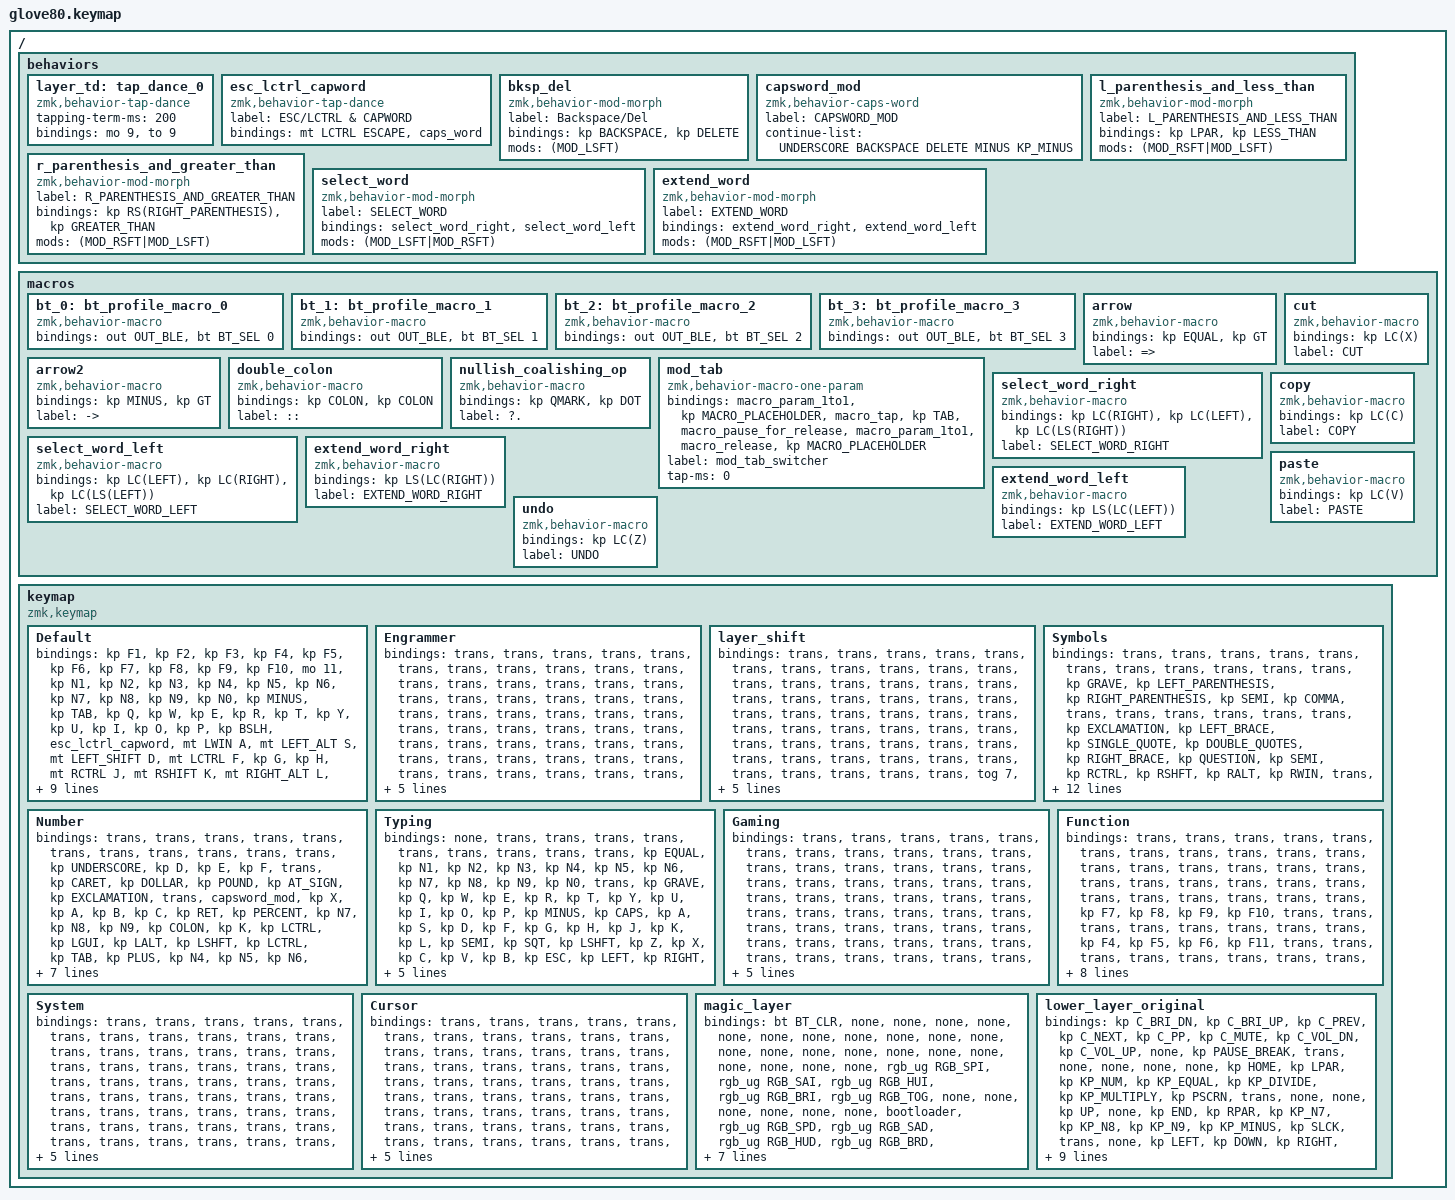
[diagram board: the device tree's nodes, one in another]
/*
 * Copyright (c) 2020 The ZMK Contributors
 *
 * SPDX-License-Identifier: MIT
 */

#include <behaviors.dtsi>
#include <dt-bindings/zmk/bt.h>
#include <dt-bindings/zmk/keys.h>
#include <dt-bindings/zmk/outputs.h>
#include <dt-bindings/zmk/rgb.h>

// layers

#define DEFAULT 0
#define LOWER 1
#define MAGIC 2

/ {
    behaviors {
        // For the "layer" key, it'd nice to be able to use it as either a shift or a toggle.
        // Configure it as a tap dance, so the first tap (or hold) is a &mo and the second tap is a &to

        layer_td: tap_dance_0 {
            compatible = "zmk,behavior-tap-dance";
            #binding-cells = <0>;
            tapping-term-ms = <200>;
            bindings = <&mo 9>, <&to 9>;
        };

        esc_lctrl_capword: esc_lctrl_capword {
            compatible = "zmk,behavior-tap-dance";
            label = "ESC/LCTRL & CAPWORD";
            #binding-cells = <0>;
            bindings = <&mt LCTRL ESCAPE>, <&caps_word>;
        };

        bksp_del: bksp_del {
            compatible = "zmk,behavior-mod-morph";
            label = "Backspace/Del";
            bindings = <&kp BACKSPACE>, <&kp DELETE>;

            #binding-cells = <0>;
            mods = <(MOD_LSFT)>;
        };

        capsword_mod: capsword_mod {
            compatible = "zmk,behavior-caps-word";
            label = "CAPSWORD_MOD";
            #binding-cells = <0>;
            continue-list = <UNDERSCORE BACKSPACE DELETE MINUS KP_MINUS>;
        };

        l_parenthesis_and_less_than: l_parenthesis_and_less_than {
            compatible = "zmk,behavior-mod-morph";
            label = "L_PARENTHESIS_AND_LESS_THAN";
            bindings = <&kp LPAR>, <&kp LESS_THAN>;

            #binding-cells = <0>;
            mods = <(MOD_RSFT|MOD_LSFT)>;
        };

        r_parenthesis_and_greater_than: r_parenthesis_and_greater_than {
            compatible = "zmk,behavior-mod-morph";
            label = "R_PARENTHESIS_AND_GREATER_THAN";
            bindings = <&kp RS(RIGHT_PARENTHESIS)>, <&kp GREATER_THAN>;

            #binding-cells = <0>;
            mods = <(MOD_RSFT|MOD_LSFT)>;
        };

        select_word: select_word {
            compatible = "zmk,behavior-mod-morph";
            label = "SELECT_WORD";
            bindings = <&select_word_right>, <&select_word_left>;

            #binding-cells = <0>;
            mods = <(MOD_LSFT|MOD_RSFT)>;
        };

        extend_word: extend_word {
            compatible = "zmk,behavior-mod-morph";
            label = "EXTEND_WORD";
            bindings = <&extend_word_right>, <&extend_word_left>;

            #binding-cells = <0>;
            mods = <(MOD_RSFT|MOD_LSFT)>;
        };
    };

    macros {
        bt_0: bt_profile_macro_0 {
            compatible = "zmk,behavior-macro";
            #binding-cells = <0>;
            bindings = <&out OUT_BLE &bt BT_SEL 0>;
        };

        bt_1: bt_profile_macro_1 {
            compatible = "zmk,behavior-macro";
            #binding-cells = <0>;
            bindings = <&out OUT_BLE &bt BT_SEL 1>;
        };

        bt_2: bt_profile_macro_2 {
            compatible = "zmk,behavior-macro";
            #binding-cells = <0>;
            bindings = <&out OUT_BLE &bt BT_SEL 2>;
        };

        bt_3: bt_profile_macro_3 {
            compatible = "zmk,behavior-macro";
            #binding-cells = <0>;
            bindings = <&out OUT_BLE &bt BT_SEL 3>;
        };

        arrow: arrow {
            compatible = "zmk,behavior-macro";
            #binding-cells = <0>;
            bindings = <&kp EQUAL &kp GT>;
            label = "=>";
        };

        arrow2: arrow2 {
            compatible = "zmk,behavior-macro";
            #binding-cells = <0>;
            bindings = <&kp MINUS &kp GT>;
            label = "->";
        };

        double_colon: double_colon {
            compatible = "zmk,behavior-macro";
            #binding-cells = <0>;
            bindings = <&kp COLON &kp COLON>;
            label = "::";
        };

        nullish_coalishing_op: nullish_coalishing_op {
            compatible = "zmk,behavior-macro";
            #binding-cells = <0>;
            bindings = <&kp QMARK &kp DOT>;
            label = "?.";
        };

        mod_tab: mod_tab {
            compatible = "zmk,behavior-macro-one-param";
            #binding-cells = <1>;
            bindings =
                <&macro_param_1to1 &kp MACRO_PLACEHOLDER>,
                <&macro_tap>,
                <&kp TAB>,
                <&macro_pause_for_release>,
                <&macro_param_1to1>,
                <&macro_release>,
                <&kp MACRO_PLACEHOLDER>;

            label = "mod_tab_switcher";
            tap-ms = <0>;
        };

        select_word_right: select_word_right {
            compatible = "zmk,behavior-macro";
            #binding-cells = <0>;
            bindings = <&kp LC(RIGHT) &kp LC(LEFT) &kp LC(LS(RIGHT))>;
            label = "SELECT_WORD_RIGHT";
        };

        select_word_left: select_word_left {
            compatible = "zmk,behavior-macro";
            #binding-cells = <0>;
            bindings = <&kp LC(LEFT) &kp LC(RIGHT) &kp LC(LS(LEFT))>;
            label = "SELECT_WORD_LEFT";
        };

        extend_word_right: extend_word_right {
            compatible = "zmk,behavior-macro";
            #binding-cells = <0>;
            bindings = <&kp LS(LC(RIGHT))>;
            label = "EXTEND_WORD_RIGHT";
        };

        extend_word_left: extend_word_left {
            compatible = "zmk,behavior-macro";
            #binding-cells = <0>;
            bindings = <&kp LS(LC(LEFT))>;
            label = "EXTEND_WORD_LEFT";
        };

        cut: cut {
            compatible = "zmk,behavior-macro";
            #binding-cells = <0>;
            bindings = <&kp LC(X)>;
            label = "CUT";
        };

        copy: copy {
            compatible = "zmk,behavior-macro";
            #binding-cells = <0>;
            bindings = <&kp LC(C)>;
            label = "COPY";
        };

        paste: paste {
            compatible = "zmk,behavior-macro";
            #binding-cells = <0>;
            bindings = <&kp LC(V)>;
            label = "PASTE";
        };

        undo: undo {
            compatible = "zmk,behavior-macro";
            #binding-cells = <0>;
            bindings = <&kp LC(Z)>;
            label = "UNDO";
        };
    };

    keymap {
        compatible = "zmk,keymap";

        Default {
            // ---------------------------------------------------------------------------------------------------------------------------------
            // |  F1   |  F2 |  F3 |  F4  |  F5  |                                                               |  F6   |  F7   |  F8  |   F9  |  F10 |
            // |  =    |  1  |  2  |  3   |  4   |  5   |                                                 |  6   |   7   |   8   |  9   |   0   |   -  |
            // |  TAB  |  Q  |  W  |  E   |  R   |  T   |                                                 |  Y   |   U   |   I   |  O   |   P   |   \  |
            // |  ESC  |  A  |  S  |  D   |  F   |  G   |                                                 |  H   |   J   |   K   |  L   |   ;   |   '  |
            // |   `   |  Z  |  X  |  C   |  V   |  B   | LSHFT | LCTRL | LOWER | | LGUI  | RCTRL | RSHFT |  N   |   M   |   ,   |  .   |   /   | PGUP |
            // | MAGIC | HOME| END | LEFT | RIGHT|      | BSPC  | DEL   | LALT  | | RALT  | RET   | SPACE |      |  UP   | DOWN  |  [   |   ]   | PGDN |

            bindings = <
&kp F1                       &kp F2      &kp F3          &kp F4            &kp F5                                                                                          &kp F6       &kp F7        &kp F8           &kp F9              &kp F10
&mo 11                       &kp N1      &kp N2          &kp N3            &kp N4       &kp N5                                                                     &kp N6  &kp N7       &kp N8        &kp N9           &kp N0              &kp MINUS
&kp TAB                      &kp Q       &kp W           &kp E             &kp R        &kp T                                                                      &kp Y   &kp U        &kp I         &kp O            &kp P               &kp BSLH
&esc_lctrl_capword           &mt LWIN A  &mt LEFT_ALT S  &mt LEFT_SHIFT D  &mt LCTRL F  &kp G                                                                      &kp H   &mt RCTRL J  &mt RSHIFT K  &mt RIGHT_ALT L  &mt RWIN SEMICOLON  &kp SQT
&mt LSHIFT LEFT_PARENTHESIS  &kp Z       &kp X           &kp C             &kp V        &kp B   &kp LSHFT  &kp LCTRL  &layer_td    &kp LGUI  &kp RCTRL  &kp RSHFT  &kp N   &kp M        &kp COMMA     &kp DOT          &kp SLASH           &mt RSHIFT RPAR
&mo 10                       &kp TILDE   &kp END         &kp LEFT          &kp RIGHT            &kp SPACE  &bksp_del  &sl 2        &sl 2     &kp TAB    &kp ENTER          &kp UP       &kp DOWN      &kp LBKT         &kp UNDERSCORE      &mo 10
            >;
        };

        Engrammer {
            bindings = <
&trans  &trans  &trans  &trans  &trans                                                                    &trans  &trans  &trans  &trans  &trans
&trans  &trans  &trans  &trans  &trans  &trans                                                    &trans  &trans  &trans  &trans  &trans  &trans
&trans  &trans  &trans  &trans  &trans  &trans                                                    &trans  &trans  &trans  &trans  &trans  &trans
&trans  &trans  &trans  &trans  &trans  &trans                                                    &trans  &trans  &trans  &trans  &trans  &trans
&trans  &trans  &trans  &trans  &trans  &trans  &trans  &trans  &trans    &trans  &trans  &trans  &trans  &trans  &trans  &trans  &trans  &trans
&trans  &trans  &trans  &trans  &trans          &trans  &trans  &trans    &trans  &trans  &trans          &trans  &trans  &trans  &trans  &trans
            >;
        };

        layer_shift {
            bindings = <
&trans  &trans  &trans  &trans  &trans                                                                    &trans  &trans  &trans  &trans  &trans
&trans  &trans  &trans  &trans  &trans  &trans                                                    &trans  &trans  &trans  &trans  &trans  &trans
&trans  &trans  &trans  &trans  &trans  &trans                                                    &trans  &trans  &trans  &trans  &trans  &trans
&trans  &trans  &trans  &trans  &trans  &trans                                                    &trans  &trans  &trans  &trans  &trans  &trans
&trans  &trans  &trans  &trans  &trans  &trans  &tog 7  &tog 6  &to 5     &trans  &trans  &tog 8  &trans  &trans  &trans  &trans  &trans  &trans
&trans  &trans  &trans  &trans  &trans          &tog 9  &tog 4  &trans    &trans  &trans  &tog 3          &trans  &trans  &trans  &trans  &trans
            >;
        };

        Symbols {
            bindings = <
&trans           &trans          &trans                &trans                 &trans                                                                                                        &trans                &trans       &trans     &trans                 &trans
&trans           &kp GRAVE       &kp LEFT_PARENTHESIS  &kp RIGHT_PARENTHESIS  &kp SEMI          &kp COMMA                                                                         &trans    &trans                &trans       &trans     &trans                 &trans
&kp EXCLAMATION  &kp LEFT_BRACE  &kp SINGLE_QUOTE      &kp DOUBLE_QUOTES      &kp RIGHT_BRACE   &kp QUESTION                                                                      &kp SEMI  &kp RCTRL             &kp RSHFT    &kp RALT   &kp RWIN               &trans
&kp POUND        &kp CARET       &kp EQUAL             &kp UNDER              &kp DOLLAR        &kp ASTRK                                                                         &kp DOT   &kp BSPC              &kp TAB      &kp SPACE  &kp RET                &trans
&kp AT           &kp LESS_THAN   &kp PIPE              &kp MINUS              &kp GREATER_THAN  &kp FSLH      &kp BACKSLASH  &kp PERIOD  &kp STAR         &trans  &trans  &trans  &kp FSLH  &kp DEL               &kp LS(TAB)  &trans     &trans                 &trans
&kp TILDE        &kp AMPERSAND   &kp LEFT_BRACKET      &kp RIGHT_BRACKET      &kp PLUS                        &kp PERCENT    &kp COLON   &kp SEMICOLON    &trans  &trans  &trans            &kp LEFT_PARENTHESIS  &kp LBKT     &kp RBKT   &kp RIGHT_PARENTHESIS  &trans
            >;
        };

        Number {
            bindings = <
&trans         &trans          &trans    &trans     &trans                                                                                          &trans      &trans     &trans       &trans           &trans
&trans         &kp UNDERSCORE  &kp D     &kp E      &kp F      &trans                                                                  &kp CARET    &kp DOLLAR  &kp POUND  &kp AT_SIGN  &kp EXCLAMATION  &trans
&capsword_mod  &kp X           &kp A     &kp B      &kp C      &kp RET                                                                 &kp PERCENT  &kp N7      &kp N8     &kp N9       &kp COLON        &kp K
&kp LCTRL      &kp LGUI        &kp LALT  &kp LSHFT  &kp LCTRL  &kp TAB                                                                 &kp PLUS     &kp N4      &kp N5     &kp N6       &kp MINUS        &kp J
&trans         &trans          &trans    &trans     &kp BSPC   &kp SPACE  &trans  &trans  &trans    &kp LS(LT)  &kp LS(GT)  &kp EQUAL  &kp STAR     &kp N1      &kp N2     &kp N3       &kp FSLH         &kp G
&trans         &trans          &trans    &trans     &kp DEL               &trans  &trans  &to 0     &kp COMMA   &kp DOT     &kp N0                  &trans      &kp LBKT   &kp RBKT     &trans           &kp TILDE
            >;
        };

        Typing {
            bindings = <
&none      &trans     &trans  &trans  &trans                                                                                &trans  &trans     &trans    &trans    &trans
&kp EQUAL  &kp N1     &kp N2  &kp N3  &kp N4  &kp N5                                                                &kp N6  &kp N7  &kp N8     &kp N9    &kp N0    &trans
&kp GRAVE  &kp Q      &kp W   &kp E   &kp R   &kp T                                                                 &kp Y   &kp U   &kp I      &kp O     &kp P     &kp MINUS
&kp CAPS   &kp A      &kp S   &kp D   &kp F   &kp G                                                                 &kp H   &kp J   &kp K      &kp L     &kp SEMI  &kp SQT
&kp LSHFT  &kp Z      &kp X   &kp C   &kp V   &kp B   &kp ESC    &kp LEFT  &kp RIGHT    &kp DOWN  &kp UP   &trans   &kp N   &kp M   &kp COMMA  &kp DOT   &kp FSLH  &kp RSHFT
&trans     &kp GRAVE  &arrow  &trans  &trans          &kp SPACE  &kp BSPC  &trans       &trans    &kp TAB  &kp RET          &trans  &kp LBKT   &kp RBKT  &trans    &trans
            >;
        };

        Gaming {
            bindings = <
&trans  &trans  &trans  &trans  &trans                                                                    &trans  &trans  &trans  &trans  &trans
&trans  &trans  &trans  &trans  &trans  &trans                                                    &trans  &trans  &trans  &trans  &trans  &trans
&trans  &trans  &trans  &trans  &trans  &trans                                                    &trans  &trans  &trans  &trans  &trans  &trans
&trans  &trans  &trans  &trans  &trans  &trans                                                    &trans  &trans  &trans  &trans  &trans  &trans
&trans  &trans  &trans  &trans  &trans  &trans  &trans  &trans  &trans    &trans  &trans  &trans  &trans  &trans  &trans  &trans  &trans  &trans
&trans  &trans  &trans  &trans  &trans          &trans  &trans  &trans    &trans  &trans  &trans          &trans  &trans  &trans  &trans  &trans
            >;
        };

        Function {
            bindings = <
&trans  &trans  &trans  &trans  &trans                                                                                            &trans                    &trans                &trans                &trans                    &trans
&trans  &trans  &trans  &trans  &trans  &trans                                                                            &trans  &trans                    &trans                &trans                &trans                    &trans
&trans  &trans  &trans  &trans  &trans  &trans                                                                            &trans  &kp F7                    &kp F8                &kp F9                &kp F10                   &trans
&trans  &trans  &trans  &trans  &trans  &trans                                                                            &trans  &kp F4                    &kp F5                &kp F6                &kp F11                   &trans
&trans  &trans  &trans  &trans  &trans  &trans  &trans  &trans  &trans    &trans      &trans             &trans           &trans  &kp F1                    &kp F2                &kp F3                &kp F12                   &trans
&trans  &trans  &trans  &trans  &trans          &trans  &trans  &trans    &kp K_MUTE  &kp C_VOLUME_DOWN  &kp C_VOLUME_UP          &kp C_BRIGHTNESS_MAXIMUM  &kp C_BRIGHTNESS_INC  &kp C_BRIGHTNESS_DEC  &kp C_BRIGHTNESS_MINIMUM  &kp C_BRIGHTNESS_AUTO
            >;
        };

        System {
            bindings = <
&trans  &trans  &trans  &trans  &trans                                                                    &trans  &trans  &trans  &trans  &trans
&trans  &trans  &trans  &trans  &trans  &trans                                                    &trans  &trans  &trans  &trans  &trans  &trans
&trans  &trans  &trans  &trans  &trans  &trans                                                    &trans  &trans  &trans  &trans  &trans  &trans
&trans  &trans  &trans  &trans  &trans  &trans                                                    &trans  &trans  &trans  &trans  &trans  &trans
&trans  &trans  &trans  &trans  &trans  &trans  &trans  &trans  &trans    &trans  &trans  &trans  &trans  &trans  &trans  &trans  &trans  &trans
&trans  &trans  &trans  &trans  &trans          &trans  &trans  &trans    &trans  &trans  &trans          &trans  &trans  &trans  &trans  &trans
            >;
        };

        Cursor {
            bindings = <
&trans  &trans  &trans  &trans  &trans                                                                    &trans  &trans  &trans  &trans  &trans
&trans  &trans  &trans  &trans  &trans  &trans                                                    &trans  &trans  &trans  &trans  &trans  &trans
&trans  &trans  &trans  &trans  &trans  &trans                                                    &trans  &trans  &trans  &trans  &trans  &trans
&trans  &trans  &trans  &trans  &trans  &trans                                                    &trans  &trans  &trans  &trans  &trans  &trans
&trans  &trans  &trans  &trans  &trans  &trans  &trans  &trans  &trans    &trans  &trans  &trans  &trans  &trans  &trans  &trans  &trans  &trans
&trans  &trans  &trans  &trans  &trans          &trans  &trans  &trans    &trans  &trans  &trans          &trans  &trans  &trans  &trans  &trans
            >;
        };

        magic_layer {
            bindings = <
&bt BT_CLR   &none            &none            &none            &none                                                                                       &none  &none  &none  &none  &none
&none        &none            &none            &none            &none            &none                                                               &none  &none  &none  &none  &none  &none
&none        &rgb_ug RGB_SPI  &rgb_ug RGB_SAI  &rgb_ug RGB_HUI  &rgb_ug RGB_BRI  &rgb_ug RGB_TOG                                                     &none  &none  &none  &none  &none  &none
&bootloader  &rgb_ug RGB_SPD  &rgb_ug RGB_SAD  &rgb_ug RGB_HUD  &rgb_ug RGB_BRD  &rgb_ug RGB_EFF                                                     &none  &none  &none  &none  &none  &bootloader
&sys_reset   &none            &none            &none            &none            &none            &bt_2  &bt_3  &none           &none  &none  &none  &none  &none  &none  &none  &none  &sys_reset
&none        &none            &none            &none            &none                             &bt_0  &bt_1  &out OUT_USB    &none  &none  &none         &none  &none  &none  &none  &none
            >;
        };

        lower_layer_original {
            bindings = <
&kp C_BRI_DN  &kp C_BRI_UP  &kp C_PREV  &kp C_NEXT  &kp C_PP                                                                           &kp C_MUTE  &kp C_VOL_DN  &kp C_VOL_UP   &none            &kp PAUSE_BREAK
&trans        &none         &none       &none       &none      &kp HOME                                                     &kp LPAR   &kp KP_NUM  &kp KP_EQUAL  &kp KP_DIVIDE  &kp KP_MULTIPLY  &kp PSCRN
&trans        &none         &none       &kp UP      &none      &kp END                                                      &kp RPAR   &kp KP_N7   &kp KP_N8     &kp KP_N9      &kp KP_MINUS     &kp SLCK
&trans        &none         &kp LEFT    &kp DOWN    &kp RIGHT  &kp PG_UP                                                    &kp PRCNT  &kp KP_N4   &kp KP_N5     &kp KP_N6      &kp KP_PLUS      &none
&trans        &kp K_CMENU   &none       &kp F11     &kp F12    &kp PG_DN  &trans  &trans  &to 0     &trans  &trans  &trans  &kp COMMA  &kp KP_N1   &kp KP_N2     &kp KP_N3      &kp KP_ENTER     &trans
&trans        &kp CAPS      &kp INS     &kp F11     &kp F12               &trans  &trans  &trans    &trans  &trans  &trans             &kp KP_N0   &kp KP_N0     &kp KP_DOT     &kp KP_ENTER     &trans
            >;
        };
    };
};
